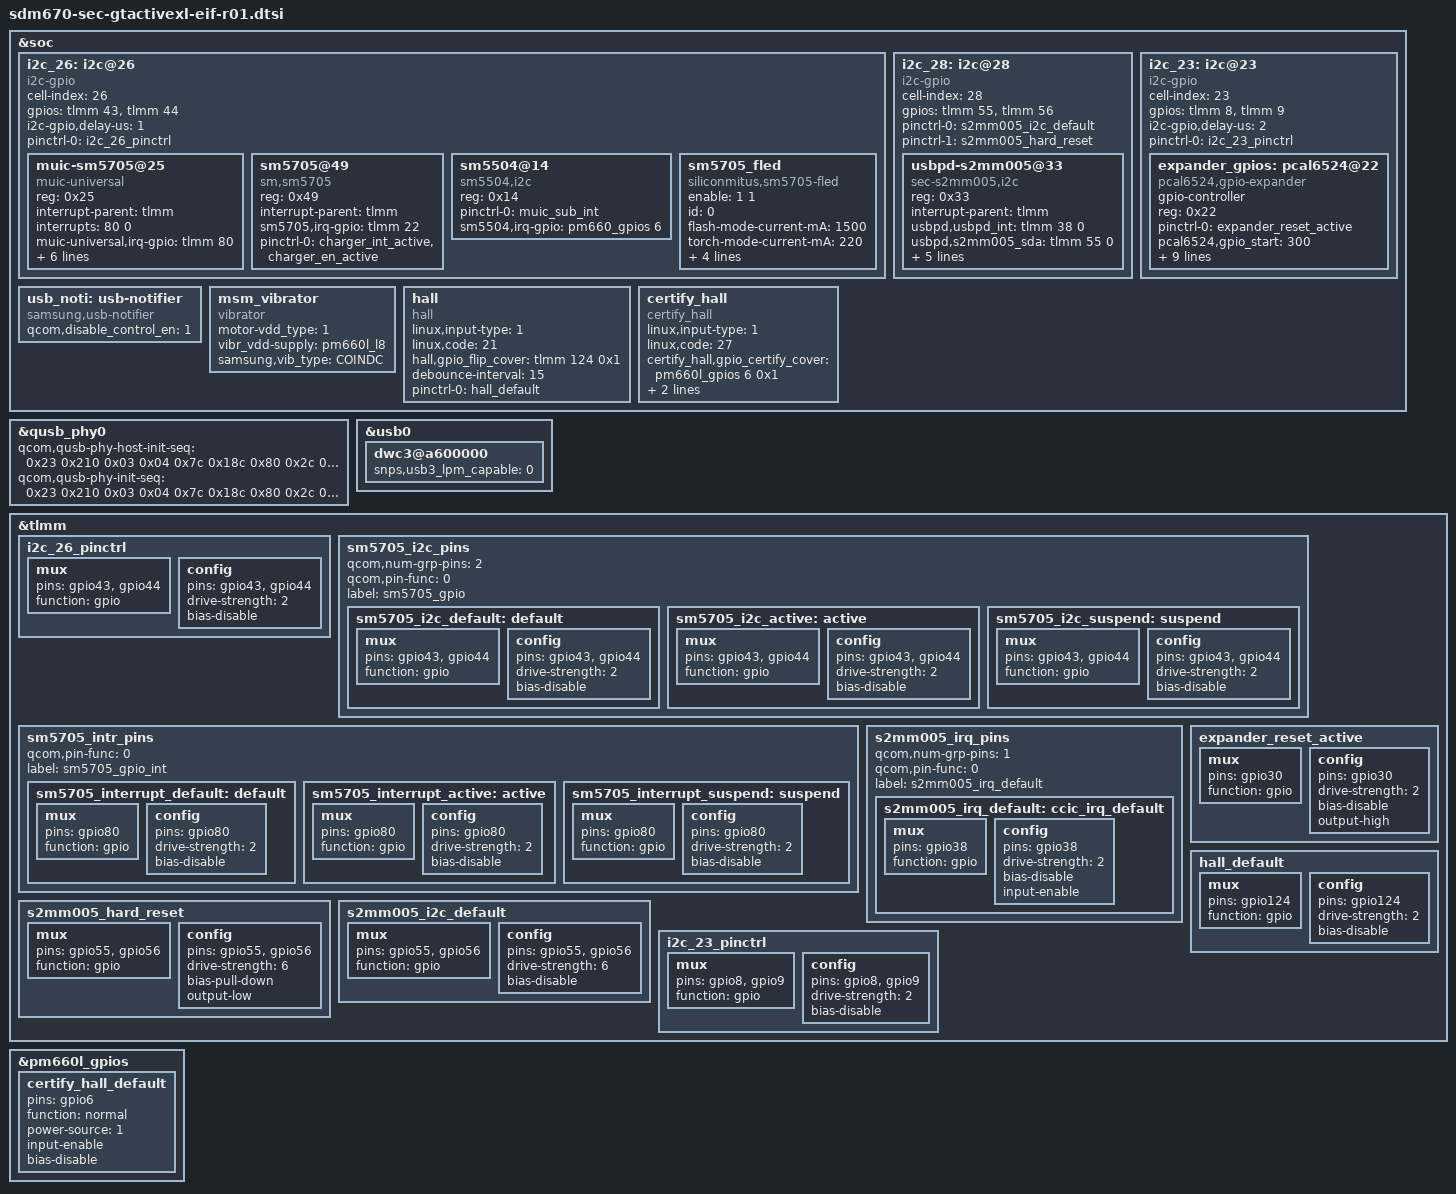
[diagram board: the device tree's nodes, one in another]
/* Copyright (c) 2018, The Linux Foundation. All rights reserved.
 *
 * This program is free software; you can redistribute it and/or modify
 * it under the terms of the GNU General Public License version 2 and
 * only version 2 as published by the Free Software Foundation.
 *
 * This program is distributed in the hope that it will be useful,
 * but WITHOUT ANY WARRANTY; without even the implied warranty of
 * MERCHANTABILITY or FITNESS FOR A PARTICULAR PURPOSE.  See the
 * GNU General Public License for more details.
 */


&soc {
	/* MUIC */
	i2c_26: i2c@26 {
		status = "ok";

		cell-index = <26>;
		compatible = "i2c-gpio";
		gpios = <&tlmm 43 0	/* IF_PMIC_SDA_1P8 */
			 &tlmm 44 0	/* IF_PMIC_SCL_1P8 */
		>;
		i2c-gpio,delay-us = <1>;
		#address-cells = <1>;
		#size-cells = <0>;

		pinctrl-names = "default";
		pinctrl-0 = <&i2c_26_pinctrl>;

		muic-sm5705@25 {
			status = "okay";
			compatible = "muic-universal";
			reg = <0x25>;
			interrupt-parent = <&tlmm>;
			interrupts = <80 0>;
			muic-universal,irq-gpio = <&tlmm 80 0x00>;
			sm5705,wakeup;
			muic-universal,chip_name = "sm,sm5705";
			muic-universal,afc-support = <1>;
			pinctrl-names = "muic_interrupt_pins_default";
			pinctrl-0 = <&sm5705_interrupt_default>;
			muic,sm5705_switch_gpio = <&tlmm 98 0>;
			muic,mux_sel = <&tlmm 50 0>;
		};
		sm5705@49{
			compatible = "sm,sm5705";
			reg = <0x49>;
			interrupt-parent = <&tlmm>;
			sm5705,irq-gpio = <&tlmm 22 0x00>;
			pinctrl-names = "default";
			pinctrl-0 = <&charger_int_active>,
						<&charger_en_active>;
/*			sm5705,mrstb-gpio = <&tlmm 87 0x00>;*/
		};
		sm5504@14{
			status = "okay";
			compatible = "sm5504,i2c";
			reg = <0x14>;
			pinctrl-names = "default";
			pinctrl-0 = <&muic_sub_int>;
			sm5504,irq-gpio = <&pm660_gpios 6 0x00>;
		};
		sm5705_fled{
			compatible = "siliconmitus,sm5705-fled";
			enable = <1 1>;
			id= <0>;
			status = "okay";
			flash-mode-current-mA = <1500>;
			torch-mode-current-mA = <220>;
			preflash-mode-current-mA = <220>;
			used-gpio-control = <1>;
			flash-en-gpio = <&expander_gpios 14 0x00>;
			torch-en-gpio = <&expander_gpios 9  0x00>;
		};
	};

	/* CCIC */
	i2c_28: i2c@28 {
		status = "okay";

		cell-index = <28>;
		compatible = "i2c-gpio";
		gpios = <&tlmm 55 0	/* CCIC_I2C_SDA_1P8 */
			 &tlmm 56 0	/* CCIC_I2C_SCL_1P8 */
		>;
		#address-cells = <1>;
		#size-cells = <0>;

		pinctrl-names = "default","hard_reset";
		pinctrl-0 = <&s2mm005_i2c_default>;
		pinctrl-1 = <&s2mm005_hard_reset>;

		usbpd-s2mm005@33 {
			compatible = "sec-s2mm005,i2c";
			reg = <0x33>;
			interrupt-parent = <&tlmm>;
			usbpd,usbpd_int = <&tlmm 38 0>;
			usbpd,s2mm005_sda = <&tlmm 55 0>;
			usbpd,s2mm005_scl = <&tlmm 56 0>;
			usbpd,aux-en-gpio = <&pm660l_gpios 3 0>;   /* Required only LPM mode */
			pinctrl-names = "default";
			pinctrl-0 = <&s2mm005_irq_default>;
			usbpd,s2mm005_fw_product_id = <0x14>;
			support_pd_role_swap;
		};
	};

	/* GPIO EXPANDER */
	i2c_23: i2c@23 {
		status = "ok";

		cell-index = <23>;
		compatible = "i2c-gpio";
		gpios = <&tlmm 8 0	/* EXPANDER_I2C_SDA_1P8 */
			 &tlmm 9 0	/* EXPANDER_I2C_SCL_1P8 */
		>;
		i2c-gpio,delay-us = <2>;
		#address-cells = <1>;
		#size-cells = <0>;

		pinctrl-names = "default";
		pinctrl-0 = <&i2c_23_pinctrl>;

		expander_gpios: pcal6524@22 {
			compatible = "pcal6524,gpio-expander";
			gpio-controller;
			#gpio-cells = <2>;
			reg = <0x22>;
			pinctrl-names = "expander_reset_setting";
			pinctrl-0 = <&expander_reset_active>;
			pcal6524,gpio_start = <300>;
			pcal6524,ngpio = <24>;
			pcal6524,reset-gpio = <&tlmm 30 0>;
			pcal6524,vdd-supply = <&pm660_l13>;
			pcal6524,support_initialize = <1>;
			/* config, 24 ~ 0, 1bit configure[1:input, 0:output]*/
			pcal6524,config = <0x7F7FBF>;    /* P2[01111111] P1[01111111] P0[10111111] */
			/* data_out, 24 ~ 0, 1bit configure[1:high, 0:low]*/
			pcal6524,data_out = <0x000000>;  /* P2[00000000] P1[00000000] P0[00000000] */
			/* pull_reg, 8 ~ 0, 2bit configure[00:no_pull, 01:pull_down, 10:pull_up, 11:not used] */
			pcal6524,pull_reg_p0 = <0x0000>; /* 00 00 00 00 / 00 00 00 00 */
			pcal6524,pull_reg_p1 = <0x4000>; /* 01 00 00 00 / 00 00 00 00 */
			pcal6524,pull_reg_p2 = <0x0000>; /* 00 00 00 00 / 00 00 00 00 */
		};
	};

	/* USB */
	usb_noti: usb-notifier {
		compatible = "samsung,usb-notifier";
		qcom,disable_control_en = <1>;
	};

	msm_vibrator {
		compatible = "vibrator";
		motor-vdd_type = <1>; /* 0: gpio, 1: pmic */
		vibr_vdd-supply = <&pm660l_l8>;
		samsung,vib_type = "COINDC";
	};

	hall {
		status = "okay";
		compatible = "hall";
		linux,input-type = <1>;
		linux,code = <21>;
		hall,gpio_flip_cover = <&tlmm 124 0x1>;
		debounce-interval = <15>;
		pinctrl-names = "default";
		pinctrl-0 = <&hall_default>;
    };

	certify_hall {
		status = "okay";
		compatible = "certify_hall";
		linux,input-type = <1>;
		linux,code = <27>;
		certify_hall,gpio_certify_cover = <&pm660l_gpios 6 0x1>;
		debounce-interval = <15>;
		pinctrl-names = "default";
		pinctrl-0 = <&certify_hall_default>;
	};
};


/* USB phy tune */
&qusb_phy0 {
	qcom,qusb-phy-host-init-seq =
	    /* <value reg_offset> */
	       <0x23 0x210 /* PWR_CTRL1 */
		0x03 0x04  /* PLL_ANALOG_CONTROLS_TWO */
		0x7c 0x18c /* PLL_CLOCK_INVERTERS */
		0x80 0x2c  /* PLL_CMODE */
		0x0a 0x184 /* PLL_LOCK_DELAY */
		0x19 0xb4  /* PLL_DIGITAL_TIMERS_TWO */
		0x40 0x194 /* PLL_BIAS_CONTROL_1 */
		0x20 0x198 /* PLL_BIAS_CONTROL_2 */
		0x21 0x214 /* PWR_CTRL2 */
		0x00 0x220 /* IMP_CTRL1 */
		0x58 0x224 /* IMP_CTRL2 */
		0x67 0x240 /* TUNE1 */
		0x2a 0x244 /* TUNE2 */
		0xca 0x248 /* TUNE3 */
		0x01 0x24c /* TUNE4 */
		0x03 0x250 /* TUNE5 */
		0x00 0x23c /* CHG_CTRL2 */
		0x22 0x210>; /* PWR_CTRL1 */

	qcom,qusb-phy-init-seq =
	/* <value reg_offset> */
	   <0x23 0x210 /* PWR_CTRL1 */
		0x03 0x04  /* PLL_ANALOG_CONTROLS_TWO */
		0x7c 0x18c /* PLL_CLOCK_INVERTERS */
		0x80 0x2c  /* PLL_CMODE */
		0x0a 0x184 /* PLL_LOCK_DELAY */
		0x19 0xb4  /* PLL_DIGITAL_TIMERS_TWO */
		0x40 0x194 /* PLL_BIAS_CONTROL_1 */
		0x18 0x198 /* PLL_BIAS_CONTROL_2 - for GTS4LV */
		0x21 0x214 /* PWR_CTRL2 */
		0x1E 0x220 /* IMP_CTRL1 */
		0x58 0x224 /* IMP_CTRL2 */
		0x67 0x240 /* TUNE1 */
		0x29 0x244 /* TUNE2 */
		0xca 0x248 /* TUNE3 */
		0x00 0x24c /* TUNE4 */
		0x03 0x250 /* TUNE5 */
		0x00 0x23c /* CHG_CTRL2 */
		0x22 0x210>; /* PWR_CTRL1 */
};

&usb0 {
	dwc3@a600000 {
		snps,usb3_lpm_capable = <0>;
	};
};

/* pinctrl */
&tlmm {

	/* MUIC - SM5705 */
	i2c_26_pinctrl: i2c_26_pinctrl {
		mux {
			pins = "gpio43",	/* IF_PMIC_SDA_1P8 */
			       "gpio44";	/* IF_PMIC_SCL_1P8 */
			function = "gpio";
		};
		config {
			pins = "gpio43",	/* IF_PMIC_SDA_1P8 */
			       "gpio44";	/* IF_PMIC_SCL_1P8 */
			drive-strength = <2>;
			bias-disable;
		};
	};

	sm5705_i2c_pins {
		qcom,num-grp-pins = <2>;
		qcom,pin-func = <0>;
		label = "sm5705_gpio";
		sm5705_i2c_default: default {
			mux {
				pins = "gpio43", "gpio44";
				function = "gpio";
			};
			config {
				pins = "gpio43", "gpio44";
				drive-strength = <2>;
				bias-disable;
			};
		};
		sm5705_i2c_active: active {
			mux {
				pins = "gpio43", "gpio44";
				function = "gpio";
			};
			config {
				pins = "gpio43", "gpio44";
				drive-strength = <2>;
				bias-disable;
			};

		};
		sm5705_i2c_suspend: suspend {
			mux {
				pins = "gpio43", "gpio44";
				function = "gpio";
			};
			config {
				pins = "gpio43", "gpio44";
				drive-strength = <2>;
				bias-disable;
			};
		};
	};

	sm5705_intr_pins {
		qcom,pin-func = <0>;
		label = "sm5705_gpio_int";
		sm5705_interrupt_default: default {
			mux {
				pins = "gpio80";
				function = "gpio";
			};
			config {
				pins = "gpio80";
				drive-strength = <2>;
				bias-disable;
			};
		};
		sm5705_interrupt_active: active {
			mux {
				pins = "gpio80";
				function = "gpio";
			};
			config {
				pins = "gpio80";
				drive-strength = <2>;
				bias-disable;
			};
		};
		sm5705_interrupt_suspend: suspend {
			mux {
				pins = "gpio80";
				function = "gpio";
			};
			config {
				pins = "gpio80";
				drive-strength = <2>;
				bias-disable;
			};
		};
	};
	
	/* CCIC */
	s2mm005_irq_pins {
		//qcom,pins = <&gp 58>;
		qcom,num-grp-pins = <1>;
		qcom,pin-func = <0>;
		label = "s2mm005_irq_default";
		s2mm005_irq_default: ccic_irq_default {
			mux {
				pins = "gpio38";
				function = "gpio";				
			};
			config {
				pins = "gpio38";
				drive-strength = <2>;
				bias-disable;         /* No PULL */
				input-enable;
			};
		};			
	};

	s2mm005_hard_reset: s2mm005_hard_reset {
		mux {
			pins = "gpio55", "gpio56";
			function = "gpio";
		};
		config { 
			pins = "gpio55", "gpio56"; 
			drive-strength = <6>; 
			bias-pull-down;
			output-low;
		};
	};

	s2mm005_i2c_default: s2mm005_i2c_default {
		mux {
			pins = "gpio55", "gpio56";
			function = "gpio";
		};
		config {
			pins = "gpio55", "gpio56"; 
			drive-strength = <6>;
			bias-disable;
		};
	};
	
	/* GPIO EXPANDER */
	i2c_23_pinctrl: i2c_23_pinctrl {
		mux {
			pins = "gpio8",	/* EXPANDER_I2C_SDA_1P8 */
			       "gpio9";	/* EXPANDER_I2C_SCL_1P8 */
			function = "gpio";
		};
		config {
			pins = "gpio8",	/* EXPANDER_I2C_SDA_1P8 */
			       "gpio9";	/* EXPANDER_I2C_SCL_1P8 */
			drive-strength = <2>;
			bias-disable;
		};
	};

	expander_reset_active: expander_reset_active {
		mux {
			pins = "gpio30";
			function = "gpio";
		};
		config {
			pins = "gpio30";
			drive-strength = <2>;   /* 16 mA */
			bias-disable;
			output-high;
		};
	};
	
	hall_default: hall_default {
		mux {
			pins = "gpio124";
			function = "gpio";
		};
		config {
			pins = "gpio124";
			drive-strength = <2>;
			bias-disable;
		};
	};
};

&pm660l_gpios {
	certify_hall_default: certify_hall_default {
		pins = "gpio6";
		function = "normal";
		power-source = <1>;
		input-enable;
		bias-disable;
	};
};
